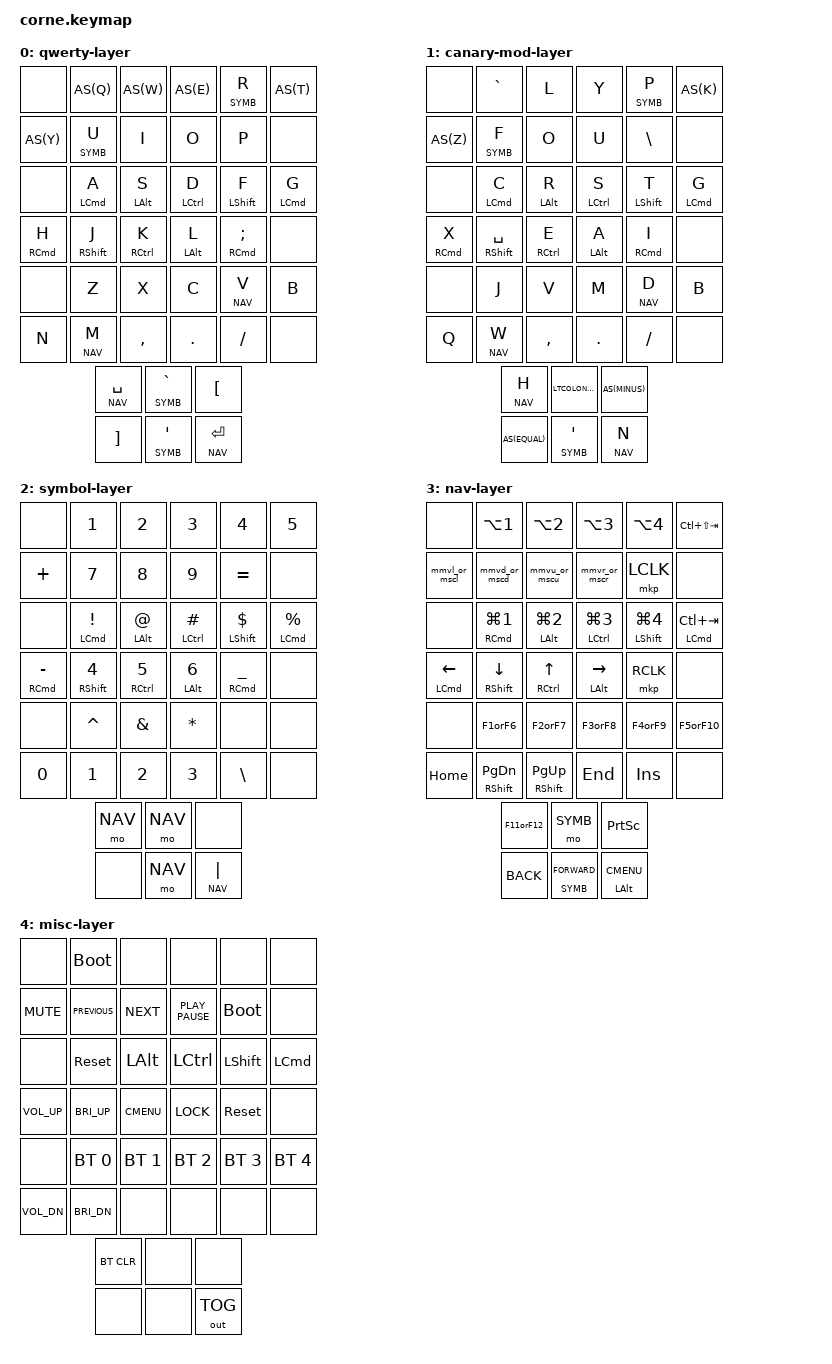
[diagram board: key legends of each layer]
/*
 * Copyright (c) 2020 The ZMK Contributors
 *
 * SPDX-License-Identifier: MIT
 */

/*
 * to build locally:
 *   west build -d build/left -b nice_nano_v2 -- -DSHIELD=corne_left -DZMK_CONFIG='../../samoklava-zmk-config/config'
 *   west build -d build/right -b nice_nano_v2 -- -DSHIELD=corne_right -DZMK_CONFIG='../../samoklava-zmk-config/config'
 */

#include <behaviors.dtsi>
#include <dt-bindings/zmk/bt.h>
#include <dt-bindings/zmk/keys.h>
#include <dt-bindings/zmk/outputs.h>

// docs/keymaps/behaviors/mouse-emulation.md
#define ZMK_POINTING_DEFAULT_MOVE_VAL 1620  // default: 600
#define ZMK_POINTING_DEFAULT_SCRL_VAL 25    // default: 10
#include <dt-bindings/zmk/pointing.h>

#define DEFAULT 0
#define CANARY 1
#define SYMBOL 2
#define NAVIGATION 3
#define MISCELLANEOUS 4
#define DFLT DEFAULT
#define CNR CANARY
#define SYMB SYMBOL
#define NAV NAVIGATION
#define MISC MISCELLANEOUS

/* this has to be used like AS(Q) not as &kp AS(Q). &as is defined below in behaviors */
#define AS(keycode) &as LS(keycode) keycode
#define CAPSORWORD &caps 0 0
#define LTCOLONSEMI(layer) &layer_colon_semi layer 0

&mt {
    // default
    flavor = "hold-preferred";
    quick-tap-ms = <180>;
    // was 180, default 200
    tapping-term-ms = <200>;
    // when tap before tapping-term-ms expires
    // docs: If set, instead of the keys listed in hold-trigger-key-positions producing a tap when pressed before tapping-term-ms expires, they instead produce a tap when released before tapping-term-ms expires.
    // https://zmk.dev/docs/keymaps/behaviors/hold-tap#positional-hold-tap-and-hold-trigger-key-positions
    hold-trigger-on-release;
    // this would help with shift+mouseclick by sending preliminary hold until tapping-term-ms expires
    // hold-while-undecided;
    // it will output tap after hold-tap was held but no other key was pressed
    // retro-tap;
};

&lt {
    // default
    flavor = "tap-preferred";
    // was 200, '-' is new syntax rather than '_' in attributes
    quick-tap-ms = <180>;
    // was 180, default 200
    tapping-term-ms = <200>;
    // when tap before tapping-term-ms expires
    hold-trigger-on-release;
};

&mmv {
    x-input-code = <INPUT_REL_X>;
    y-input-code = <INPUT_REL_Y>;
    time-to-max-speed-ms = <200>;
    acceleration-exponent = <2>;
};

&msc {
    x-input-code = <INPUT_REL_HWHEEL>;
    y-input-code = <INPUT_REL_WHEEL>;
    time-to-max-speed-ms = <200>;
    acceleration-exponent = <0>;
};

// possible problem with transform:
// for some weird reason the 5x3 transform doesn't quite work for the adjust layer, it needs an extra offset
/* / { */
/*     chosen { */
/*         zmk,matrix_transform = &five_column_transform; */
/*     }; */
/* }; */
            //                 Key positions
            //       0  1  2  3  4    5  6  7  8  9
            //      10 11 12 13 14   15 16 17 18 19
            //      20 21 22 23 24   25 26 27 28 29
            //            30 31 32   33 34 35

/ {
    behaviors {
        //                 Key positions
        //       0  1  2  3  4  5    6  7  8  9 10 11
        //      12 13 14 15 16 17   18 19 20 21 22 23
        //      24 25 26 27 28 29   30 31 32 33 34 35
        //               36 37 38   39 40 41

        // interrupt flavors: https://zmk.dev/docs/keymaps/behaviors/hold-tap#interrupt-flavors
        hml: homerow_mods_left {
            compatible = "zmk,behavior-hold-tap";
            label = "HOMEROW_MODS_LEFT";
            #binding-cells = <2>;
            // was tap-preferred, to try: hold-preferred
            flavor = "balanced";
            // for typing quickly
            require-prior-idle-ms = <125>;
            // was 250, default 200
            tapping-term-ms = <250>;
            // when tapping quickly again within this value ms it will trigger tap
            quick-tap-ms = <200>;
            bindings = <&kp>, <&kp>;
            // note that this has no actual effect for tap-preffered, only for hold-preferred or balanced
            hold-trigger-key-positions = <
                                  6  7  8  9 10
                13 14 15 16 17   18 19 20 21 22
                                 30 31 32 33 34
                      36 37 38   39 40 41
            >;
            hold-trigger-on-release;
        };

        hsl: homerow_shift_left {
            compatible = "zmk,behavior-hold-tap";
            label = "HOMEROW_SHIFT_LEFT";
            #binding-cells = <2>;
            flavor = "tap-preferred";
            require-prior-idle-ms = <50>;
            tapping-term-ms = <200>;
            quick-tap-ms = <200>;
            bindings = <&kp>, <&kp>;
            hold-trigger-key-positions = <
                                  6  7  8  9 10
                13 14 15 16 17   18 19 20 21 22
                                 30 31 32 33 34
                      36 37 38   39 40 41
            >;
            hold-trigger-on-release;
        };

        hmr: homerow_mods_right {
            compatible = "zmk,behavior-hold-tap";
            label = "HOMEROW_MODS_RIGHT";
            #binding-cells = <2>;
            flavor = "balanced";
            require-prior-idle-ms = <125>;
            tapping-term-ms = <250>;
            quick-tap-ms = <200>;
            bindings = <&kp>, <&kp>;
            hold-trigger-key-positions = <
                1  2  3  4  5
                13 14 15 16 17   18 19 20 21 22
                25 26 27 28 29
                      36 37 38   39 40 41
            >;
            hold-trigger-on-release;
        };

        hsr: homerow_shift_right {
            compatible = "zmk,behavior-hold-tap";
            label = "HOMEROW_SHIFT_RIGHT";
            #binding-cells = <2>;
            flavor = "tap-preferred";
            require-prior-idle-ms = <50>;
            tapping-term-ms = <200>;
            quick-tap-ms = <200>;
            bindings = <&kp>, <&kp>;
            hold-trigger-key-positions = <
                1  2  3  4  5
                13 14 15 16 17   18 19 20 21 22
                25 26 27 28 29
                      36 37 38   39 40 41
            >;
            hold-trigger-on-release;
        };

        // to hold e.g. q to produce Q
        as: auto_shift {
            compatible = "zmk,behavior-hold-tap";
            #binding-cells = <2>;
            tapping-term-ms = <200>;
            // not sure but this I think disables usual tap-then-tap-and-hold and always produces shift on second tap
            quick-tap-ms = <0>;
            flavor = "tap-preferred";
            bindings = <&kp>, <&kp>;
        };

        // nodelabel: nodename, refer by nodelabel while nodelabel is optional it is the only way to refer to the node using phandle &
        // to produce caplock when tap and cap_word when hold more than tapping-term-ms (default 200)
        caps: caps_or_capsword {
            compatible = "zmk,behavior-hold-tap";
            label = "CAPS_OR_CAPSWORD";
            #binding-cells = <2>;
            // default is hold-preferred
            flavor = "tap-preferred";
            bindings = <&kp>, <&caps_word>;
            // default?
            tapping-term-ms = <200>;
        };

        lock: lock {
            compatible = "zmk,behavior-tap-dance";
            label = "LOCK";
            #binding-cells = <0>;
            bindings = <&lt 2 SPACE>, <&kp K_LOCK>;
            tapping-term-ms = <200>;
        };

        // tap dance: double tap will produce lang_m, single tap layer2/enter
        lang: lang {
            compatible = "zmk,behavior-tap-dance";
            label = "LANG";
            #binding-cells = <0>;
            bindings = <&lt 2 ENTER>, <&lang_m>;
        };

        // this allows tap,hold to quickly use scroll on nav layer without modifier
        // wip: define macro with wait time and hold/tap for the second in tap tap-dance
        mmvu_mscu_dance: mmvu_mscu_dance {
            compatible = "zmk,behavior-tap-dance";
            #binding-cells = <0>;
            tapping-term-ms = <200>;
            bindings = <&mmv MOVE_UP>, <&mscu_m>;
        };

        mmvd_mscd_dance: mmvd_mscd_dance {
            compatible = "zmk,behavior-tap-dance";
            #binding-cells = <0>;
            tapping-term-ms = <200>;
            bindings = <&mmv MOVE_DOWN>, <&mscd_m>;
        };

        // using alt as modifier as it rarely needed for mouse movement and easy for one hand mouse scroll
        mmvu_or_mscu: mmvu_or_mscu {
            compatible = "zmk,behavior-mod-morph";
            label = "MMVUORMSCU";
            bindings = <&mmv MOVE_UP>, <&msc SCRL_UP>;
            //bindings = <&mmvu_mscu_dance>, <&msc SCRL_UP>;
            #binding-cells = <0>;
            mods = <(MOD_LALT)>;
        };

        mmvd_or_mscd: mmvd_or_mscd {
            compatible = "zmk,behavior-mod-morph";
            label = "MMVDORMSCD";
            bindings = <&mmv MOVE_DOWN>, <&msc SCRL_DOWN>;
            //bindings = <&mmvd_mscd_dance>, <&msc SCRL_DOWN>;
            #binding-cells = <0>;
            mods = <(MOD_LALT)>;
        };

        mmvl_or_mscl: mmvl_or_mscl {
            compatible = "zmk,behavior-mod-morph";
            label = "MMVLORMSCL";
            bindings = <&mmv MOVE_LEFT>, <&msc SCRL_LEFT>;
            #binding-cells = <0>;
            mods = <(MOD_LALT)>;
        };

        mmvr_or_mscr: mmvr_or_mscr {
            compatible = "zmk,behavior-mod-morph";
            label = "MMVRORMSCR";
            bindings = <&mmv MOVE_RIGHT>, <&msc SCRL_RIGHT>;
            #binding-cells = <0>;
            mods = <(MOD_LALT)>;
        };

        /* WIP: switching to mouse scroll by holding that key to the right */
        /* would be nice but then its impossible to distinguish actual mscr vs alt  */
        /* alt_mmvr_or_mscr: alt_mmvr_or_mscr {
         * } */

        colon_or_semi: colon_or_semi {
            compatible = "zmk,behavior-mod-morph";
            label = "COLON_OR_SEMI";
            bindings = <&kp COLON>, <&kp SEMI>;
            #binding-cells = <0>;
            mods = <(MOD_LSFT|MOD_RSFT)>;
        };

        // a placeholder like 0 should be used when using this in keymap, cause it expects 2 args
        layer_colon_semi: layer_colon_semi {
            compatible = "zmk,behavior-hold-tap";
            label = "LAYER_HOLD_COLON_SEMI";
            flavor = "tap-preferred";
            #binding-cells = <2>;
            bindings = <&mo>, <&colon_or_semi>;
            tapping-term-ms = <200>;
        };

        F1orF6: F1orF6 {
            compatible = "zmk,behavior-mod-morph";
            label = "F1ORF6";
            bindings = <&kp F1>, <&kp F6>;
            #binding-cells = <0>;
            mods = <(MOD_LSFT|MOD_RSFT)>;
        };

        F2orF7: F2orF7 {
            compatible = "zmk,behavior-mod-morph";
            label = "F2ORF7";
            bindings = <&kp F2>, <&kp F7>;
            #binding-cells = <0>;
            mods = <(MOD_LSFT|MOD_RSFT)>;
        };

        F3orF8: F3orF8 {
            compatible = "zmk,behavior-mod-morph";
            label = "F3ORF8";
            bindings = <&kp F3>, <&kp F8>;
            #binding-cells = <0>;
            mods = <(MOD_LSFT|MOD_RSFT)>;
        };

        F4orF9: F4orF9 {
            compatible = "zmk,behavior-mod-morph";
            label = "F4ORF9";
            bindings = <&kp F4>, <&kp F9>;
            #binding-cells = <0>;
            mods = <(MOD_LSFT|MOD_RSFT)>;
        };

        F5orF10: F5orF10 {
            compatible = "zmk,behavior-mod-morph";
            label = "F5ORF10";
            bindings = <&kp F5>, <&kp F10>;
            #binding-cells = <0>;
            mods = <(MOD_LSFT|MOD_RSFT)>;
        };

        F11orF12: F11orF12 {
            compatible = "zmk,behavior-mod-morph";
            label = "F11ORF12";
            bindings = <&kp F11>, <&kp F12>;
            #binding-cells = <0>;
            mods = <(MOD_LSFT|MOD_RSFT)>;
        };

        tog_on: toggle_layer_on_only {
            compatible = "zmk,behavior-toggle-layer";
            #binding-cells = <1>;
            display-name = "Toggle Layer On";
            toggle-mode = "on";
        };

        tog_off: toggle_layer_off_only {
            compatible = "zmk,behavior-toggle-layer";
            #binding-cells = <1>;
            display-name = "Toggle Layer Off";
            toggle-mode = "off";
        };
    };

    combos {
        compatible = "zmk,combos";

        // tap for capsword, hold for caps
        capsAQ {
            bindings = <CAPSORWORD>;
            key-positions = <1 13>;
        };

        capswordZA {
            bindings = <&caps_word>;
            key-positions = <25 13>;
        };

        escJK {
            bindings = <&kp ESC>;
            key-positions = <19 20>;
        };

        tabDF {
            bindings = <&kp TAB>;
            key-positions = <15 16>;
        };

        bspcPCOLONdflt {
            bindings = <&kp BSPC>;
            key-positions = <10 22>;
        };

        // hit both l/r mouse click buttons on nav layer
        mkpmclkPCOLONnav {
            bindings = <&mkp MCLK>;
            key-positions = <10 22>;
            layers = <NAV>;
        };

        delSEMIFSLH {
            bindings = <&kp DEL>;
            key-positions = <22 34>;
        };

        /* now this is occupied by nav layer toggle */
        /* spcCV { */
        /*     bindings = <&kp SPACE>; */
        /*     key-positions = <27 28>; */
        /* }; */

        retCOMMAM {
            bindings = <&kp RET>;
            key-positions = <32 31>;
        };

        lsqbrRT {
            bindings = <&kp LBKT>;
            key-positions = <4 5>;
        };

        rsqbrYU {
            bindings = <&kp RBKT>;
            key-positions = <6 7>;
        };

        lsqparFG {
            bindings = <&kp LPAR>;
            key-positions = <16 17>;
        };

        rsqparHJ {
            bindings = <&kp RPAR>;
            key-positions = <18 19>;
        };

        rcurlMN {
            bindings = <&kp RBRC>;
            key-positions = <30 31>;
        };

        lcurlVB {
            bindings = <&kp LBRC>;
            key-positions = <29 28>;
        };

        to-default-kl {
            bindings = <&to_default>;
            key-positions = <20 21>;  // kl
        };

        to-canary-sd {
            bindings = <&to_canary>;
            key-positions = <14 15>;  // sd
            /* layers = <DFLT CANARY>; */
        };

        to-symb-ui {
            bindings = <&to_symbol>;
            key-positions = <7 8>;  // ui
            /* layers = <DFLT CANARY SYMB>; */
        };

        to-symb-er {
            bindings = <&to_symbol>;
            key-positions = <3 4>;  // er
            /* layers = <DFLT CANARY SYMB>; */
        };

        to-nav-cv {
            bindings = <&to_nav>;
            key-positions = <27 28>;  // cv
            /* layers = <DFLT CANARY NAV>; */
        };

        // m, is occuppied by enter
        to-nav-rthumb-m {
            bindings = <&to_nav>;
            key-positions = <31 41>;  // rthumb+m
            /* layers = <DFLT CANARY NAV>; */
        };

        // v+spc for symmetry on the left
        to-nav-lthumb-v {
            bindings = <&to_nav>;
            key-positions = <28 36>;  // lthumb+v
            /* layers = <DFLT CANARY NAV>; */
        };

        // would this work for conditional layer?
        // no it doesn't, as per warning note at the bottom of https://zmk.dev/docs/keymaps/conditional-layers
        // conditional layer only activated when if-layers conditions are fully met
        /* to-misc-2rthumb { */
        /*     bindings = <&to_misc>; */
        /*     key-positions = <40 41>;  // 2rthumb */
        /* }; */
    };

    conditional_layers {
        compatible = "zmk,conditional-layers";
        tri_layer {
            if-layers = <SYMB NAV>;
            then-layer = <MISC>;
        };
    };

    macros {
        lang_m: lang_m {
            compatible = "zmk,behavior-macro";
            label = "LANG_M";
            #binding-cells = <0>;
            bindings =
                <&macro_press>,
                <&kp LCMD>,
                <&macro_tap>,
                <&kp SPACE>,
                <&macro_release>,
                <&kp LCMD>;
        };

        mscu_m: mscu_m {
            compatible = "zmk,behavior-macro";
            label = "MSCU_M";
            //wait-ms = <30>;
            //tap-ms = <40>;
            #binding-cells = <0>;
            bindings = <&macro_tap_time 500>, <&msc SCRL_UP>;
        };

        mscd_m: mscd_m {
            compatible = "zmk,behavior-macro";
            label = "MSCD_M";
            //wait-ms = <30>;
            //tap-ms = <40>;
            #binding-cells = <0>;
            bindings = <&macro_tap_time 500>, <&msc SCRL_DOWN>;
        };

        to_default: to_default {
            compatible = "zmk,behavior-macro";
            label = "TO_DFLT";
            #binding-cells = <0>;
            bindings =
                <&macro_tap>,
                <&to DFLT>,
                <&macro_tap>,
                <&kp F14>;
        };

        to_canary: to_canary {
            compatible = "zmk,behavior-macro";
            label = "TO_CANARY";
            #binding-cells = <0>;
            bindings =
                <&macro_tap>,
                <&to CANARY>,
                <&macro_tap>,
                <&kp F15>;
        };

        to_symbol: to_symbol {
            compatible = "zmk,behavior-macro";
            label = "TO_SYMBOL";
            #binding-cells = <0>;
            bindings =
                <&macro_tap>,
                <&to SYMB>,
                <&macro_tap>,
                <&kp F16>;
        };

        to_nav: to_nav {
            compatible = "zmk,behavior-macro";
            label = "TO_NAV";
            #binding-cells = <0>;
            bindings =
                <&macro_tap>,
                <&to NAV>,
                <&macro_tap>,
                <&kp F17>;
        };
    };

    // todo:
    //  - toggle layer for browser nav ctrl+tab / ctrl+shift+tab, for tmux nav, for windows nav (F13,..)
    //  - try usb logging, output selection for usb logging if needed (adjust layer)
    //  - read all configuration docs
    // notes:
    //  - keycodes: https://zmk.dev/docs/keymaps/list-of-keycodes
    //  - undo/redo/copy/cut/paste are not registered on emacs termux android (TUCPro) but registered on linux i3 as XF86.. and undo/redo registered in emacs
    //  - contextmenu is registered globally on android (TUCPro) - e.g. termux menu works, chrome page menu
    //  - forward/back are registered globally on android (TUCPro) - e.g. chrome page forward/back, termux just goes to home on 'back'
    //  - scrolllock doesn't have effect on android, scrollup/scrolldown essentially work like pgup/pgdn (<prior>/<next> in emacs) but bound to XF86Scroll.. on 
    //  - right alt does't work on android for some reason, for now using left alt only
    //  - soft_off - this is actually only needed for some keyboards without power switch
    keymap {
        compatible = "zmk,keymap";
        default_layer {  // layer 0
            display-name = "qwerty-layer";
            // q w e r t  y u i o p
            // a s d f g  h j k l ;
            // z x c v b  n m , . /
            //   spc ` [  ] ' ret
            bindings = <
&none AS(Q) AS(W) AS(E) &lt SYMB R AS(T)
                       AS(Y) &lt SYMB U &kp I &kp O &kp P &none
&none &hml LCMD A &hml LALT S &hml LCTRL D &hsl LSHFT F &hml LCMD G
                        &hmr RCMD H &hsr RSHFT J &hmr RCTRL K &hmr LALT L &hmr RCMD SEMI &none
&none &kp Z &kp X &kp C &lt NAV V &kp B
                        &kp N &lt NAV M &kp COMMA &kp DOT &kp FSLH &none
      &lt NAV SPACE &lt SYMB GRAVE &kp LBKT
                        &kp RBKT &lt SYMB SQT &lt NAV RET
            >;
        };

        canary_mod_layer {  // layer 1
            display-name = "canary-mod-layer";
            // ` l y p k  z f o u \
            // c r s t g  x   e a i
            // j v m d b  q w , . /
            //     h : -  = ' n
            bindings = <
&none &kp GRAVE &kp L &kp Y &lt SYMB P AS(K)
                        AS(Z) &lt SYMB F &kp O &kp U &kp BSLH &none
&none &hml LCMD C &hml LALT R &hml LCTRL S &hsl LSHFT T &hml LCMD G
                        &hmr RCMD X &hsr RSHFT SPACE &hmr RCTRL E &hmr LALT A &hmr RCMD I &none
&none &kp J &kp V &kp M &lt NAV D &kp B
                        &kp Q &lt NAV W &kp COMMA &kp DOT &kp FSLH &none
      &lt NAV H LTCOLONSEMI(SYMB) AS(MINUS)
                        AS(EQUAL) &lt SYMB SQT &lt NAV N
            >;
            // todo: -+ =_
        };

        symbol_layer {  // layer 2
            display-name = "symbol-layer";
            bindings = <
&none &kp N1 &kp N2 &kp N3 &kp N4 &kp N5
                          &kp PLUS &kp N7 &kp N8 &kp N9 &kp EQUAL &none
&none &hml LCMD EXCL &hml LALT AT &hml LCTRL HASH &hsl LSHFT DLLR &hml LCMD PRCNT
                          &hmr RCMD MINUS &hsr RSHFT N4 &hmr RCTRL N5 &hmr LALT N6 &hmr RCMD UNDER &none
&none &kp CARET &kp AMPS &kp ASTRK &none &none
                          &kp N0 &kp N1 &kp N2 &kp N3 &kp BSLH &none
      &mo NAV &mo NAV &none
                          &none &mo NAV &lt NAV PIPE
            >;
        };

        nav_layer {  // layer 3
            display-name = "nav-layer";
            // do i need &msc SCRL_DOWN/SCRL_UP/SCRL_RIGHT/SCRL_LEFT
            bindings = <
&none &kp LA(N1) &kp LA(N2) &kp LA(N3) &kp LA(N4) &kp LC(LS(TAB))
                          &mmvl_or_mscl &mmvd_or_mscd &mmvu_or_mscu &mmvr_or_mscr &mkp LCLK &none
&none &hml RCMD LG(N1) &hml LALT LG(N2) &hml LCTRL LG(N3) &hsl LSHFT LG(N4) &hml LCMD LC(TAB)
                          &hmr LCMD LEFT &hsr RSHFT DOWN &hmr RCTRL UP &hmr LALT RIGHT &mkp RCLK &none
&none &F1orF6 &F2orF7 &F3orF8 &F4orF9 &F5orF10
                          &kp HOME &hsr RSHFT PG_DN &hsr RSHFT PG_UP &kp END &kp INS &none
      &F11orF12 &mo SYMB &kp PSCRN
                          &kp K_BACK &lt SYMB K_FORWARD &mt LALT K_CMENU
            >;
        };

        misc_layer {  // layer 4
            display-name = "misc-layer";
            bindings = <
&none &bootloader &none &none &none &none
                          &kp K_MUTE &kp K_PREVIOUS &kp K_NEXT &kp K_PLAY_PAUSE &bootloader &none
&none &sys_reset &kp LALT &kp LCTRL &kp LSHFT &kp LCMD
                          &kp C_VOL_UP &kp C_BRI_UP &kp K_CMENU &kp K_LOCK &sys_reset &none
&none &bt BT_SEL 0 &bt BT_SEL 1 &bt BT_SEL 2 &bt BT_SEL 3 &bt BT_SEL 4
                          &kp C_VOL_DN &kp C_BRI_DN &none &none &none &none
      &bt BT_CLR &none &none
                          &none &none &out OUT_TOG
            >;
        };
    };
};
